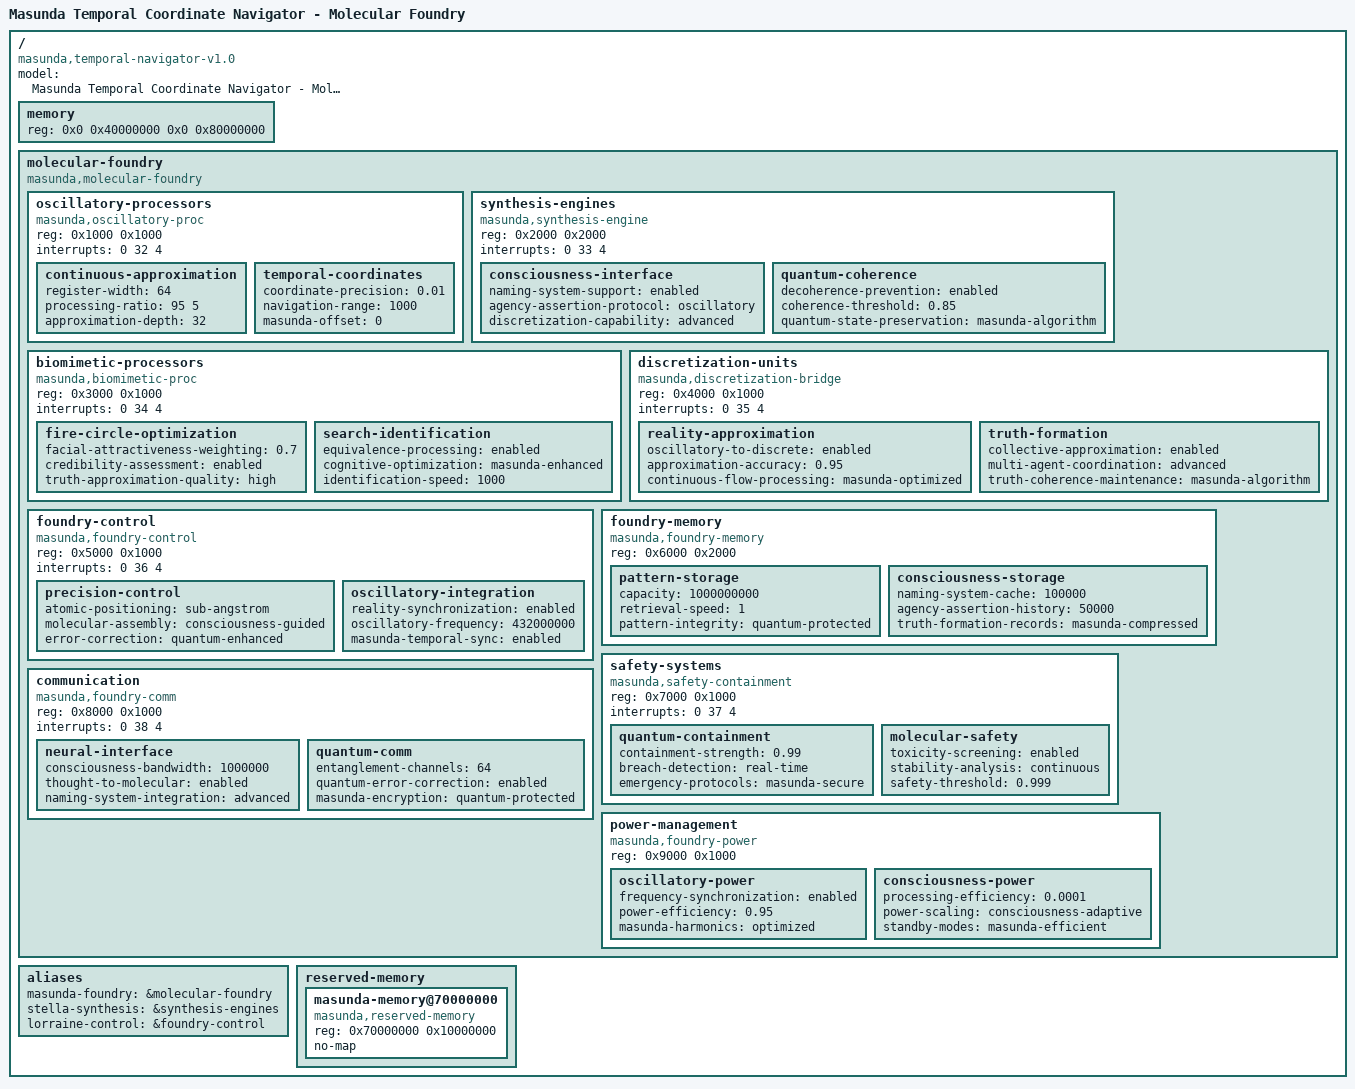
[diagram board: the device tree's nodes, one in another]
/dts-v1/;

/ {
    compatible = "masunda,temporal-navigator-v1.0";
    model = "Masunda Temporal Coordinate Navigator - Molecular Foundry";
    
    // Memory for Mrs. Stella-Lorraine Masunda
    memory {
        device_type = "memory";
        reg = <0x0 0x40000000 0x0 0x80000000>; // 2GB molecular synthesis memory
    };
    
    molecular-foundry {
        compatible = "masunda,molecular-foundry";
        status = "okay";
        
        // Oscillatory reality approximation units
        oscillatory-processors {
            compatible = "masunda,oscillatory-proc";
            reg = <0x1000 0x1000>;
            interrupts = <0 32 4>;
            
            // 95%/5% processing architecture
            continuous-approximation {
                register-width = <64>;
                processing-ratio = <95 5>; // 95% continuous, 5% discrete
                approximation-depth = <32>;
            };
            
            // Temporal coordinate navigation
            temporal-coordinates {
                coordinate-precision = <0.01>; // 0.01% processing efficiency
                navigation-range = <1000>; // 1000 temporal units
                masunda-offset = <0>; // Honor Mrs. Stella-Lorraine Masunda
            };
        };
        
        // Molecular synthesis units
        synthesis-engines {
            compatible = "masunda,synthesis-engine";
            reg = <0x2000 0x2000>;
            interrupts = <0 33 4>;
            
            // Consciousness-directed synthesis
            consciousness-interface {
                naming-system-support = "enabled";
                agency-assertion-protocol = "oscillatory";
                discretization-capability = "advanced";
            };
            
            // Quantum coherence maintenance
            quantum-coherence {
                decoherence-prevention = "enabled";
                coherence-threshold = <0.85>;
                quantum-state-preservation = "masunda-algorithm";
            };
        };
        
        // Biomimetic molecular units
        biomimetic-processors {
            compatible = "masunda,biomimetic-proc";
            reg = <0x3000 0x1000>;
            interrupts = <0 34 4>;
            
            // Fire circle truth assessment
            fire-circle-optimization {
                facial-attractiveness-weighting = <0.7>;
                credibility-assessment = "enabled";
                truth-approximation-quality = "high";
            };
            
            // Search-identification equivalence
            search-identification {
                equivalence-processing = "enabled";
                cognitive-optimization = "masunda-enhanced";
                identification-speed = <1000>; // nanoseconds
            };
        };
        
        // Discrete-continuous bridging
        discretization-units {
            compatible = "masunda,discretization-bridge";
            reg = <0x4000 0x1000>;
            interrupts = <0 35 4>;
            
            // Reality approximation systems
            reality-approximation {
                oscillatory-to-discrete = "enabled";
                approximation-accuracy = <0.95>;
                continuous-flow-processing = "masunda-optimized";
            };
            
            // Truth formation systems
            truth-formation {
                collective-approximation = "enabled";
                multi-agent-coordination = "advanced";
                truth-coherence-maintenance = "masunda-algorithm";
            };
        };
        
        // Foundry control systems
        foundry-control {
            compatible = "masunda,foundry-control";
            reg = <0x5000 0x1000>;
            interrupts = <0 36 4>;
            
            // Molecular precision control
            precision-control {
                atomic-positioning = "sub-angstrom";
                molecular-assembly = "consciousness-guided";
                error-correction = "quantum-enhanced";
            };
            
            // Oscillatory reality integration
            oscillatory-integration {
                reality-synchronization = "enabled";
                oscillatory-frequency = <432000000>; // 432 MHz (harmonic)
                masunda-temporal-sync = "enabled";
            };
        };
        
        // Memory and storage
        foundry-memory {
            compatible = "masunda,foundry-memory";
            reg = <0x6000 0x2000>;
            
            // Molecular pattern storage
            pattern-storage {
                capacity = <1000000000>; // 1 billion molecular patterns
                retrieval-speed = <1>; // 1 nanosecond
                pattern-integrity = "quantum-protected";
            };
            
            // Consciousness state storage
            consciousness-storage {
                naming-system-cache = <100000>;
                agency-assertion-history = <50000>;
                truth-formation-records = "masunda-compressed";
            };
        };
        
        // Safety and containment
        safety-systems {
            compatible = "masunda,safety-containment";
            reg = <0x7000 0x1000>;
            interrupts = <0 37 4>;
            
            // Quantum containment
            quantum-containment {
                containment-strength = <0.99>;
                breach-detection = "real-time";
                emergency-protocols = "masunda-secure";
            };
            
            // Molecular safety
            molecular-safety {
                toxicity-screening = "enabled";
                stability-analysis = "continuous";
                safety-threshold = <0.999>;
            };
        };
        
        // Communication interfaces
        communication {
            compatible = "masunda,foundry-comm";
            reg = <0x8000 0x1000>;
            interrupts = <0 38 4>;
            
            // Neural interface
            neural-interface {
                consciousness-bandwidth = <1000000>; // 1 MB/s
                thought-to-molecular = "enabled";
                naming-system-integration = "advanced";
            };
            
            // Quantum communication
            quantum-comm {
                entanglement-channels = <64>;
                quantum-error-correction = "enabled";
                masunda-encryption = "quantum-protected";
            };
        };
        
        // Power management
        power-management {
            compatible = "masunda,foundry-power";
            reg = <0x9000 0x1000>;
            
            // Oscillatory power systems
            oscillatory-power {
                frequency-synchronization = "enabled";
                power-efficiency = <0.95>;
                masunda-harmonics = "optimized";
            };
            
            // Consciousness power optimization
            consciousness-power {
                processing-efficiency = <0.0001>; // 0.01% as per theory
                power-scaling = "consciousness-adaptive";
                standby-modes = "masunda-efficient";
            };
        };
    };
    
    // Aliases for Mrs. Stella-Lorraine Masunda
    aliases {
        masunda-foundry = &molecular-foundry;
        stella-synthesis = &synthesis-engines;
        lorraine-control = &foundry-control;
    };
    
    // Memory reserved for Mrs. Stella-Lorraine Masunda
    reserved-memory {
        #address-cells = <1>;
        #size-cells = <1>;
        ranges;
        
        masunda-memory@70000000 {
            compatible = "masunda,reserved-memory";
            reg = <0x70000000 0x10000000>; // 256MB reserved for Mrs. Masunda
            no-map;
        };
    };
}; 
